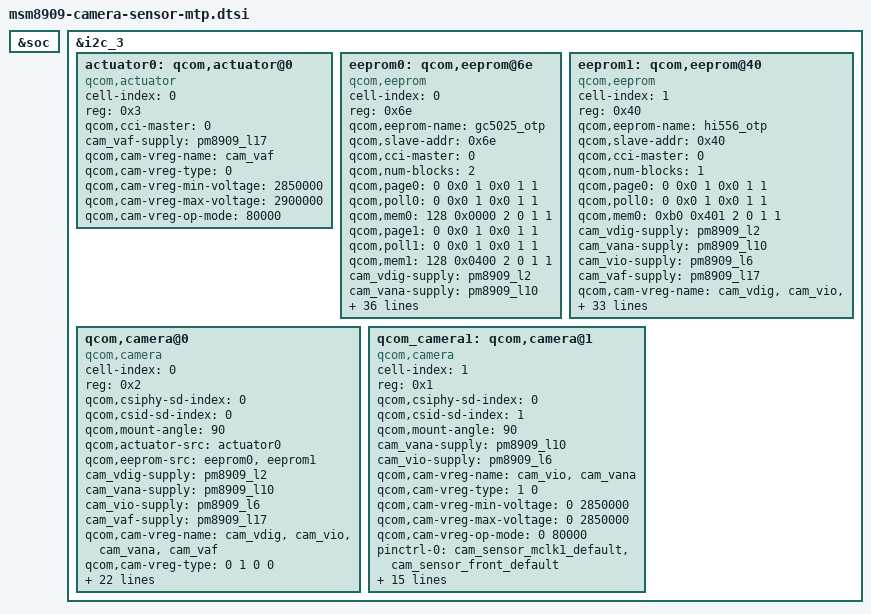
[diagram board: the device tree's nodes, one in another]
/*
 * Copyright (c) 2014-2017, The Linux Foundation. All rights reserved.
 *
 * This program is free software; you can redistribute it and/or modify
 * it under the terms of the GNU General Public License version 2 and
 * only version 2 as published by the Free Software Foundation.
 *
 * This program is distributed in the hope that it will be useful,
 * but WITHOUT ANY WARRANTY; without even the implied warranty of
 * MERCHANTABILITY or FITNESS FOR A PARTICULAR PURPOSE.  See the
 * GNU General Public License for more details.
 */

&soc {
};
&i2c_3 {

	actuator0: qcom,actuator@0 {
		cell-index = <0>;
		reg = <0x3>;
		compatible = "qcom,actuator";
		qcom,cci-master = <0>;
		cam_vaf-supply = <&pm8909_l17>;
		qcom,cam-vreg-name = "cam_vaf";
		qcom,cam-vreg-type = <0>;
		qcom,cam-vreg-min-voltage = <2850000>;
		qcom,cam-vreg-max-voltage = <2900000>;
		qcom,cam-vreg-op-mode = <80000>;
	};

	eeprom0: qcom,eeprom@6e {
		cell-index = <0>;
		reg = <0x6e>;
                qcom,eeprom-name = "gc5025_otp";
		compatible = "qcom,eeprom";
		qcom,slave-addr = <0x6e>;
		qcom,cci-master = <0>;
		qcom,num-blocks = <2>;

		qcom,page0 = <0 0x0 1 0x0 1 1>;
		qcom,poll0 = <0 0x0 1 0x0 1 1>;
		qcom,mem0 = <128 0x0000 2 0 1 1>;

		qcom,page1 = <0 0x0 1 0x0 1 1>;
		qcom,poll1 = <0 0x0 1 0x0 1 1>;
		qcom,mem1 = <128 0x0400 2 0 1 1>;

		cam_vdig-supply = <&pm8909_l2>;
		cam_vana-supply = <&pm8909_l10>;
		cam_vio-supply = <&pm8909_l6>;
		cam_vaf-supply = <&pm8909_l17>;
		qcom,cam-vreg-name = "cam_vdig", "cam_vio", "cam_vana",
							"cam_vaf";
		qcom,cam-vreg-type = <0 1 0 0>;
		qcom,cam-vreg-min-voltage = <1200000 0 2800000 2850000>;
		qcom,cam-vreg-max-voltage = <1200000 0 2850000 2900000>;
		qcom,cam-vreg-op-mode = <200000 0 80000 100000>;
		qcom,enable_pinctrl;
		pinctrl-names = "cam_default", "cam_suspend";
		pinctrl-0 = <&cam_sensor_mclk0_default
					&cam_sensor_rear_default>;
		pinctrl-1 = <&cam_sensor_mclk0_sleep &cam_sensor_rear_sleep>;
		gpios = <&msm_gpio 26 0>,
			<&msm_gpio 35 0>,
			<&msm_gpio 34 0>;
		qcom,gpio-reset = <1>;
		qcom,gpio-standby = <2>;
		qcom,gpio-req-tbl-num = <0 1 2>;
		qcom,gpio-req-tbl-flags = <1 0 0>;
		qcom,gpio-req-tbl-label = "CAMIF_MCLK",
						"CAM_RESET1",
						"CAM_STANDBY";
		qcom,cam-power-seq-type =
			"sensor_gpio", 
                        "sensor_gpio",
                        "sensor_vreg",
                        "sensor_vreg",
                        "sensor_vreg",
                        "sensor_clk",
			"sensor_gpio", 
                        "sensor_gpio";
		qcom,cam-power-seq-val =
                	"sensor_gpio_reset",
			"sensor_gpio_standby",
                        "cam_vio",
                        "cam_vdig",
                        "cam_vana",
                        "sensor_cam_mclk",
			"sensor_gpio_reset",
			"sensor_gpio_standby";
		qcom,cam-power-seq-cfg-val = <0 0 1 1 1 24000000 1 1>;
		qcom,cam-power-seq-delay = <1 1 10 10 10 10 1 1>;
                status = "ok";
		clocks = <&clock_gcc clk_mclk0_clk_src>,
			<&clock_gcc clk_gcc_camss_mclk0_clk>;
		clock-names = "cam_src_clk", "cam_clk";
		qcom,clock-rates = <19200000 0>;
	};

	eeprom1: qcom,eeprom@40 {
		cell-index = <1>;
		reg = <0x40>;
                qcom,eeprom-name = "hi556_otp";
		compatible = "qcom,eeprom";
		qcom,slave-addr = <0x40>;
		qcom,cci-master = <0>;
		qcom,num-blocks = <1>;

		qcom,page0 = <0 0x0 1 0x0 1 1>;
		qcom,poll0 = <0 0x0 1 0x0 1 1>;
		qcom,mem0 = <0xb0 0x401 2 0 1 1>;

		cam_vdig-supply = <&pm8909_l2>;
		cam_vana-supply = <&pm8909_l10>;
		cam_vio-supply = <&pm8909_l6>;
		cam_vaf-supply = <&pm8909_l17>;
		qcom,cam-vreg-name = "cam_vdig", "cam_vio", "cam_vana",
							"cam_vaf";
		qcom,cam-vreg-type = <0 1 0 0>;
		qcom,cam-vreg-min-voltage = <1200000 0 2800000 2850000>;
		qcom,cam-vreg-max-voltage = <1200000 0 2850000 2900000>;
		qcom,cam-vreg-op-mode = <200000 0 80000 100000>;
		qcom,enable_pinctrl;
		pinctrl-names = "cam_default", "cam_suspend";
		pinctrl-0 = <&cam_sensor_mclk0_default
					&cam_sensor_rear_default>;
		pinctrl-1 = <&cam_sensor_mclk0_sleep &cam_sensor_rear_sleep>;
		gpios = <&msm_gpio 26 0>,
			<&msm_gpio 35 0>,
			<&msm_gpio 34 0>;
		qcom,gpio-reset = <1>;
		qcom,gpio-standby = <2>;
		qcom,gpio-req-tbl-num = <0 1 2>;
		qcom,gpio-req-tbl-flags = <1 0 0>;
		qcom,gpio-req-tbl-label = "CAMIF_MCLK",
						"CAM_RESET1",
						"CAM_STANDBY";
		qcom,cam-power-seq-type =
			"sensor_gpio", 
                        "sensor_gpio",
                        "sensor_vreg",
                        "sensor_vreg",
                        "sensor_vreg",
                        "sensor_clk",
			"sensor_gpio", 
                        "sensor_gpio";
		qcom,cam-power-seq-val =
                	"sensor_gpio_reset",
			"sensor_gpio_standby",
                        "cam_vio",
                        "cam_vdig",
                        "cam_vana",
                        "sensor_cam_mclk",
			"sensor_gpio_reset",
			"sensor_gpio_standby";
		qcom,cam-power-seq-cfg-val = <0 0 1 1 1 24000000 1 1>;
		qcom,cam-power-seq-delay = <1 1 10 10 10 10 1 1>;
                status = "ok";
		clocks = <&clock_gcc clk_mclk0_clk_src>,
			<&clock_gcc clk_gcc_camss_mclk0_clk>;
		clock-names = "cam_src_clk", "cam_clk";
		qcom,clock-rates = <19200000 0>;
	};
	/*led_flash0: qcom,led-flash@60 {
		cell-index = <0>;
		reg = <0x60>;
		qcom,slave-id = <0x60 0x00 0x0011>;
		compatible = "qcom,led-flash";
		label = "adp1660";
		qcom,flash-type = <1>;
		qcom,gpio-no-mux = <0>;
		qcom,enable_pinctrl;
		pinctrl-names = "cam_flash_default", "cam_flash_suspend";
		pinctrl-0 = <&cam_sensor_flash_default>;
		pinctrl-1 = <&cam_sensor_flash_sleep>;
		gpios = <&msm_gpio 31 0>,
			<&msm_gpio 32 0>,
			<&msm_gpio 36 0>;
		qcom,gpio-flash-en = <0>;
		qcom,gpio-flash-now = <1>;
		qcom,gpio-flash-rst = <2>;
		qcom,gpio-req-tbl-num = <0 1 2>;
		qcom,gpio-req-tbl-flags = <0 0 0>;
		qcom,gpio-req-tbl-label = "FLASH_EN",
			"FLASH_NOW", "FLASH_RST";
		qcom,cci-master = <0>;
	};*/

	qcom,camera@0 {
		cell-index = <0>;
		compatible = "qcom,camera";
		reg = <0x2>;
		qcom,csiphy-sd-index = <0>;
		qcom,csid-sd-index = <0>;
		qcom,mount-angle = <90>;
		qcom,actuator-src = <&actuator0>;
		///qcom,led-flash-src = <&led_flash0>;
                qcom,eeprom-src = <&eeprom0 &eeprom1>;
		cam_vdig-supply = <&pm8909_l2>;
		cam_vana-supply = <&pm8909_l10>;
		cam_vio-supply = <&pm8909_l6>;
		cam_vaf-supply = <&pm8909_l17>;
		qcom,cam-vreg-name = "cam_vdig", "cam_vio", "cam_vana","cam_vaf";
		qcom,cam-vreg-type = <0 1 0 0>;
		qcom,cam-vreg-min-voltage = <1200000 0 2800000 2850000>;
		qcom,cam-vreg-max-voltage = <1200000 0 2850000 2900000>;
		qcom,cam-vreg-op-mode = <200000 0 80000 100000>;
		pinctrl-names = "cam_default", "cam_suspend";
		pinctrl-0 = <&cam_sensor_mclk0_default
				&cam_sensor_rear_default>;
		pinctrl-1 = <&cam_sensor_mclk0_sleep &cam_sensor_rear_sleep>;
		gpios = <&msm_gpio 26 0>,
			<&msm_gpio 35 0>,
			<&msm_gpio 34 0>;
		qcom,gpio-reset = <1>;
		qcom,gpio-standby = <2>;
		qcom,gpio-req-tbl-num = <0 1 2>;
		qcom,gpio-req-tbl-flags = <1 0 0>;
		qcom,gpio-req-tbl-label = "CAMIF_MCLK",
			"CAM_RESET1",
			"CAM_STANDBY";
		qcom,sensor-position = <0>;
		qcom,sensor-mode = <0>;
		qcom,cci-master = <0>;
		status = "ok";
		clocks = <&clock_gcc clk_mclk0_clk_src>,
				<&clock_gcc clk_gcc_camss_mclk0_clk>;
		clock-names = "cam_src_clk", "cam_clk";
		qcom,clock-rates = <24000000 0>;
	};

	qcom_camera1: qcom,camera@1 {
		cell-index = <1>;
		compatible = "qcom,camera";
		reg = <0x1>;
		qcom,csiphy-sd-index = <0>;
		qcom,csid-sd-index = <1>;
		qcom,mount-angle = <90>;
		cam_vana-supply = <&pm8909_l10>;
		cam_vio-supply = <&pm8909_l6>;
		qcom,cam-vreg-name = "cam_vio", "cam_vana";
		qcom,cam-vreg-type = <1 0>;
		qcom,cam-vreg-min-voltage = <0 2850000>;
		qcom,cam-vreg-max-voltage = <0 2850000>;
		qcom,cam-vreg-op-mode = <0 80000>;
		pinctrl-names = "cam_default", "cam_suspend";
		pinctrl-0 = <&cam_sensor_mclk1_default &cam_sensor_front_default>;
		pinctrl-1 = <&cam_sensor_mclk1_sleep &cam_sensor_front_sleep>;
		gpios = <&msm_gpio 27 0>,
			<&msm_gpio 28 0>,
			<&msm_gpio 33 0>;
		qcom,gpio-reset = <1>;
		qcom,gpio-standby = <2>;
		qcom,gpio-req-tbl-num = <0 1 2>;
		qcom,gpio-req-tbl-flags = <1 0 0>;
		qcom,gpio-req-tbl-label = "CAMIF_MCLK",
			"CAM_RESET",
			"CAM_STANDBY";
		qcom,cci-master = <0>;
		qcom,sensor-position = <1>;
		qcom,sensor-mode = <0>;
		status = "ok";
		clocks = <&clock_gcc clk_mclk1_clk_src>,
				<&clock_gcc clk_gcc_camss_mclk1_clk>;
		clock-names = "cam_src_clk", "cam_clk";
		qcom,clock-rates = <24000000 0>;
	};
};
